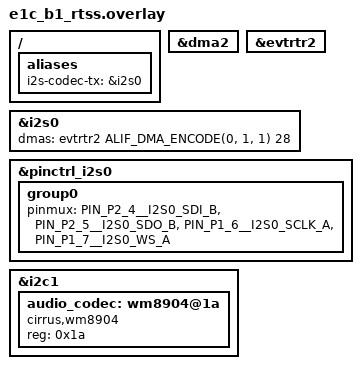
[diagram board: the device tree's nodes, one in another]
/* Copyright (C) Alif Semiconductor - All Rights Reserved.
 * Use, distribution and modification of this code is permitted under the
 * terms stated in the Alif Semiconductor Software License Agreement
 *
 * You should have received a copy of the Alif Semiconductor Software
 * License Agreement with this file. If not, please write to:
 * contact@alifsemi.com, or visit: https://alifsemi.com/license
 *
 */
#include <zephyr/dt-bindings/dma/alif_dma_event_router.h>
/ {
	aliases {
		i2s-codec-tx = &i2s0;
	};
};

&dma2 {
	status = "okay";
};
&evtrtr2 {
	status = "okay";
};
&i2s0 {
	/*
	 * Cell 0: ALIF_DMA_ENCODE(channel, dma_group, handshake)
	 *   - channel: Physical DMA channel (0 for TX)
	 *   - dma_group: Input source selection (1)
	 *   - handshake: Enable hardware handshaking (1 for I2S)
	 * Cell 1: Peripheral request number (28 for TX)
	 */
	dmas = <&evtrtr2 ALIF_DMA_ENCODE(0, 1, 1) 28>;
	dma-names = "txdma";
	status = "okay";
};
&pinctrl_i2s0 {
	group0 {
		pinmux = <PIN_P2_4__I2S0_SDI_B>,
			 <PIN_P2_5__I2S0_SDO_B>,
			 <PIN_P1_6__I2S0_SCLK_A>,
			 <PIN_P1_7__I2S0_WS_A>;
	};
};

&i2c1 {
	status = "okay";

	audio_codec: wm8904@1a {
		compatible = "cirrus,wm8904";
		reg = <0x1a>;
		status = "okay";
	};
};
